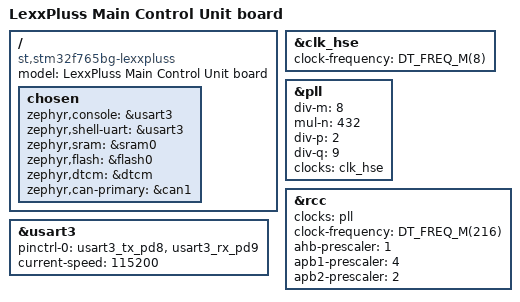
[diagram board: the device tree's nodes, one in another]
/dts-v1/;
#include <st/f7/stm32f765Xg.dtsi>
#include <st/f7/stm32f765b(g-i)tx-pinctrl.dtsi>

/ {
	model = "LexxPluss Main Control Unit board";
	compatible = "st,stm32f765bg-lexxpluss";

	chosen {
		zephyr,console = &usart3;
		zephyr,shell-uart = &usart3;
		zephyr,sram = &sram0;
		zephyr,flash = &flash0;
		zephyr,dtcm = &dtcm;
		zephyr,can-primary = &can1;
	};
};

&clk_hse {
	clock-frequency = <DT_FREQ_M(8)>;
	status = "okay";
};

&pll {
	div-m = <8>;
	mul-n = <432>;
	div-p = <2>;
	div-q = <9>;
	clocks = <&clk_hse>;
	status = "okay";
};

&rcc {
	clocks = <&pll>;
	clock-frequency = <DT_FREQ_M(216)>;
	ahb-prescaler = <1>;
	apb1-prescaler = <4>;
	apb2-prescaler = <2>;
};

&usart3 {
	pinctrl-0 = <&usart3_tx_pd8 &usart3_rx_pd9>;
	current-speed = <115200>;
	status = "okay";
};
